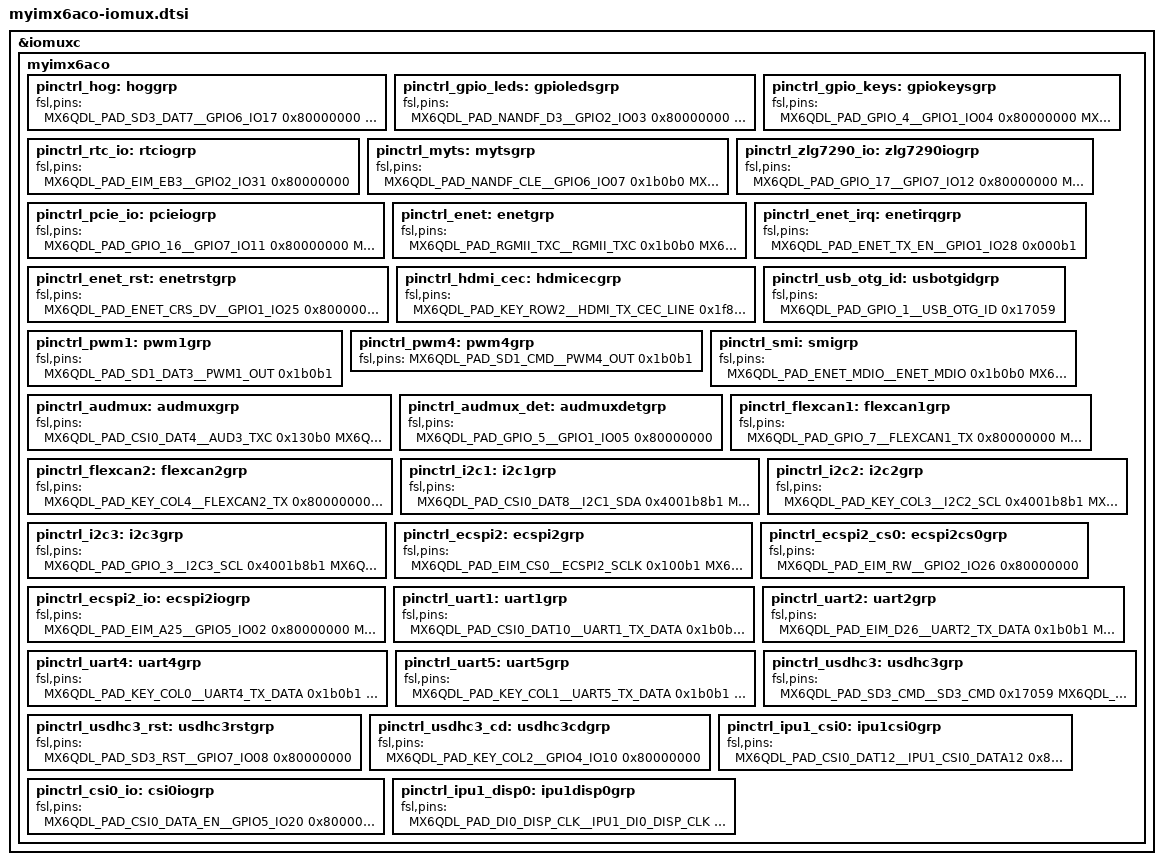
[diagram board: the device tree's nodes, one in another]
/*
 * MYZR Technology Co.,Ltd
 * http://www.myzr.com.cn
 * Tang Bin <tangb@myzr.com.cn>
 */

&iomuxc {
	myimx6aco {
		pinctrl_hog: hoggrp {
			fsl,pins = <
				MX6QDL_PAD_SD3_DAT7__GPIO6_IO17		0x80000000
				MX6QDL_PAD_SD3_DAT6__GPIO6_IO18		0x80000000
				MX6QDL_PAD_SD1_DAT0__GPIO1_IO16		0x80000000
				MX6QDL_PAD_SD1_DAT1__SD1_DATA1		0x80000000
				MX6QDL_PAD_SD1_CLK__GPIO1_IO20		0x80000000
				MX6QDL_PAD_SD1_DAT2__GPIO1_IO19		0x80000000
				MX6QDL_PAD_GPIO_19__GPIO4_IO05		0x80000000
				MX6QDL_PAD_EIM_D30__GPIO3_IO30		0x80000000
				MX6QDL_PAD_NANDF_CS3__GPIO6_IO16	0x80000000
				MX6QDL_PAD_SD2_CLK__GPIO1_IO10		0x80000000
				MX6QDL_PAD_EIM_D23__GPIO3_IO23		0x80000000
				MX6QDL_PAD_EIM_D24__GPIO3_IO24		0x80000000
				MX6QDL_PAD_EIM_D25__GPIO3_IO25		0x80000000
				MX6QDL_PAD_EIM_D31__GPIO3_IO31		0x80000000
				MX6QDL_PAD_SD2_DAT0__GPIO1_IO15		0x80000000
				MX6QDL_PAD_SD2_DAT3__GPIO1_IO12		0x80000000
				MX6QDL_PAD_SD2_DAT2__GPIO1_IO13		0x80000000
				MX6QDL_PAD_SD2_CMD__GPIO1_IO11		0x80000000
				MX6QDL_PAD_SD2_DAT1__GPIO1_IO14		0x80000000
				MX6QDL_PAD_EIM_D22__GPIO3_IO22		0x80000000
				MX6QDL_PAD_EIM_D21__GPIO3_IO21		0x80000000
				MX6QDL_PAD_EIM_DA0__GPIO3_IO00		0x80000000
				MX6QDL_PAD_EIM_DA9__GPIO3_IO09		0x80000000
				MX6QDL_PAD_EIM_DA5__GPIO3_IO05		0x80000000
				MX6QDL_PAD_EIM_BCLK__GPIO6_IO31		0x80000000
				MX6QDL_PAD_EIM_DA13__GPIO3_IO13		0x80000000
				MX6QDL_PAD_EIM_DA14__GPIO3_IO14		0x80000000
				MX6QDL_PAD_EIM_DA11__GPIO3_IO11		0x80000000
				MX6QDL_PAD_EIM_EB1__GPIO2_IO29		0x80000000
				MX6QDL_PAD_EIM_DA4__GPIO3_IO04		0x80000000
				MX6QDL_PAD_EIM_EB0__GPIO2_IO28		0x80000000
				MX6QDL_PAD_EIM_DA10__GPIO3_IO10		0x80000000
				MX6QDL_PAD_EIM_DA2__GPIO3_IO02		0x80000000
				MX6QDL_PAD_EIM_WAIT__GPIO5_IO00		0x80000000
				MX6QDL_PAD_EIM_DA15__GPIO3_IO15		0x80000000
				MX6QDL_PAD_DI0_PIN4__GPIO4_IO20		0x80000000
				MX6QDL_PAD_EIM_DA1__GPIO3_IO01		0x80000000
				MX6QDL_PAD_EIM_DA6__GPIO3_IO06		0x80000000
				MX6QDL_PAD_EIM_DA3__GPIO3_IO03		0x80000000
				MX6QDL_PAD_EIM_DA8__GPIO3_IO08		0x80000000
				MX6QDL_PAD_EIM_DA7__GPIO3_IO07		0x80000000
				MX6QDL_PAD_EIM_DA12__GPIO3_IO12		0x80000000
				MX6QDL_PAD_EIM_LBA__GPIO2_IO27		0x80000000
				
				MX6QDL_PAD_SD3_DAT5__GPIO7_IO00		0x80000000
				MX6QDL_PAD_SD3_DAT4__GPIO7_IO01		0x80000000
				
				MX6QDL_PAD_GPIO_2__GPIO1_IO02		0x80000000 /* USB_HUB_nRST */
				MX6QDL_PAD_GPIO_9__GPIO1_IO09		0x80000000 /* WDOG_B */
				
				MX6QDL_PAD_GPIO_0__CCM_CLKO1    	0x130b0
				
				/* MX6QDL_PAD_EIM_D20__GPIO3_IO20, NC */
				/* MX6QDL_PAD_NANDF_D2__GPIO2_IO02, NC */
			>;
		};
		
		pinctrl_gpio_leds: gpioledsgrp {
			fsl,pins = <
				MX6QDL_PAD_NANDF_D3__GPIO2_IO03		0x80000000 /* D10 */
				MX6QDL_PAD_ENET_RXD1__GPIO1_IO26	0x80000000 /* D11 */
				MX6QDL_PAD_ENET_TXD0__GPIO1_IO30	0x80000000 /* D12 */
				MX6QDL_PAD_ENET_RX_ER__GPIO1_IO24	0x80000000 /* D13 */
				MX6QDL_PAD_ENET_TXD1__GPIO1_IO29	0x80000000 /* D16 */
				MX6QDL_PAD_NANDF_D0__GPIO2_IO00		0x80000000 /* D17 */
				MX6QDL_PAD_NANDF_D5__GPIO2_IO05		0x80000000 /* D18 */
				MX6QDL_PAD_ENET_RXD0__GPIO1_IO27	0x80000000 /* D19 */
			>;
		};
		
		pinctrl_gpio_keys: gpiokeysgrp {
			fsl,pins = <
				MX6QDL_PAD_GPIO_4__GPIO1_IO04  		0x80000000 /* WAKE_UP */
				MX6QDL_PAD_NANDF_CS2__GPIO6_IO15	0x80000000 /* KEY_VOL+ */
				MX6QDL_PAD_NANDF_RB0__GPIO6_IO10	0x80000000 /* KEY_VOL- */
				MX6QDL_PAD_NANDF_WP_B__GPIO6_IO09	0x80000000 /* SW6 */
				MX6QDL_PAD_NANDF_D4__GPIO2_IO04		0x80000000 /* SW20 */
				MX6QDL_PAD_NANDF_D6__GPIO2_IO06		0x80000000 /* SW13 */
				MX6QDL_PAD_NANDF_D7__GPIO2_IO07		0x80000000 /* SW11 */
			>;
		};
		
		pinctrl_rtc_io: rtciogrp {
			fsl,pins = <
				MX6QDL_PAD_EIM_EB3__GPIO2_IO31 		0x80000000
			>;
		};
		
		pinctrl_myts: mytsgrp {
			fsl,pins = <
				MX6QDL_PAD_NANDF_CLE__GPIO6_IO07	0x1b0b0 /* TS_INT */
				MX6QDL_PAD_NANDF_D1__GPIO2_IO01		0x1b0b0 /* TS_RST */
			>;
		};
		
		pinctrl_zlg7290_io: zlg7290iogrp {
			fsl,pins = <
				MX6QDL_PAD_GPIO_17__GPIO7_IO12		0x80000000
				MX6QDL_PAD_GPIO_18__GPIO7_IO13		0x80000000
			>;
		};
		
		pinctrl_pcie_io: pcieiogrp {
			fsl,pins = <
				MX6QDL_PAD_GPIO_16__GPIO7_IO11		0x80000000
				MX6QDL_PAD_NANDF_CS1__GPIO6_IO14	0x80000000
				MX6QDL_PAD_NANDF_ALE__GPIO6_IO08	0x80000000
			>;
		};
		
		pinctrl_enet: enetgrp {
			fsl,pins = <
				MX6QDL_PAD_RGMII_TXC__RGMII_TXC			0x1b0b0
				MX6QDL_PAD_RGMII_TD0__RGMII_TD0			0x1b0b0
				MX6QDL_PAD_RGMII_TD1__RGMII_TD1			0x1b0b0
				MX6QDL_PAD_RGMII_TD2__RGMII_TD2			0x1b0b0
				MX6QDL_PAD_RGMII_TD3__RGMII_TD3			0x1b0b0
				MX6QDL_PAD_RGMII_TX_CTL__RGMII_TX_CTL	0x1b0b0
				MX6QDL_PAD_RGMII_RXC__RGMII_RXC			0x1b0b0
				MX6QDL_PAD_RGMII_RD0__RGMII_RD0			0x1b0b0
				MX6QDL_PAD_RGMII_RD1__RGMII_RD1			0x1b0b0
				MX6QDL_PAD_RGMII_RD2__RGMII_RD2			0x1b0b0
				MX6QDL_PAD_RGMII_RD3__RGMII_RD3			0x1b0b0
				MX6QDL_PAD_RGMII_RX_CTL__RGMII_RX_CTL	0x1b0b0
				MX6QDL_PAD_ENET_REF_CLK__ENET_TX_CLK	0x1b0b0
			>;
		};
		pinctrl_enet_irq: enetirqgrp {
			fsl,pins = <
				MX6QDL_PAD_ENET_TX_EN__GPIO1_IO28		0x000b1
			>;
		};
		pinctrl_enet_rst: enetrstgrp {
			fsl,pins = <
				MX6QDL_PAD_ENET_CRS_DV__GPIO1_IO25		0x80000000
			>;
		};
		
		pinctrl_hdmi_cec: hdmicecgrp {
			fsl,pins = <
				MX6QDL_PAD_KEY_ROW2__HDMI_TX_CEC_LINE	0x1f8b0
			>;
		};
		
		pinctrl_usb_otg_id: usbotgidgrp {
			fsl,pins = <
				MX6QDL_PAD_GPIO_1__USB_OTG_ID		0x17059
			>;
		};
		
		pinctrl_pwm1: pwm1grp {
			fsl,pins = <
				MX6QDL_PAD_SD1_DAT3__PWM1_OUT		0x1b0b1 /* DISP0_CONTRAST */
			>;
		};
		pinctrl_pwm4: pwm4grp {
			fsl,pins = <
				MX6QDL_PAD_SD1_CMD__PWM4_OUT		0x1b0b1
			>;
		};
		
		pinctrl_smi: smigrp {
			fsl,pins = <
				MX6QDL_PAD_ENET_MDIO__ENET_MDIO		0x1b0b0
				MX6QDL_PAD_ENET_MDC__ENET_MDC		0x1b0b0
			>;
		};
		
		pinctrl_audmux: audmuxgrp {
			fsl,pins = <
				MX6QDL_PAD_CSI0_DAT4__AUD3_TXC		0x130b0
				MX6QDL_PAD_CSI0_DAT5__AUD3_TXD		0x110b0
				MX6QDL_PAD_CSI0_DAT6__AUD3_TXFS		0x130b0
				MX6QDL_PAD_CSI0_DAT7__AUD3_RXD		0x130b0
			>;
		};
		pinctrl_audmux_det: audmuxdetgrp {
			fsl,pins = <
				MX6QDL_PAD_GPIO_5__GPIO1_IO05  		0x80000000
			>;
		};
		
		pinctrl_flexcan1: flexcan1grp {
			fsl,pins = <
				MX6QDL_PAD_GPIO_7__FLEXCAN1_TX		0x80000000
				MX6QDL_PAD_GPIO_8__FLEXCAN1_RX		0x80000000
			>;
		};
		pinctrl_flexcan2: flexcan2grp {
			fsl,pins = <
				MX6QDL_PAD_KEY_COL4__FLEXCAN2_TX	0x80000000
				MX6QDL_PAD_KEY_ROW4__FLEXCAN2_RX	0x80000000
			>;
		};
		
		pinctrl_i2c1: i2c1grp {
			fsl,pins = <
				MX6QDL_PAD_CSI0_DAT8__I2C1_SDA	0x4001b8b1
				MX6QDL_PAD_CSI0_DAT9__I2C1_SCL	0x4001b8b1
			>;
		};
		pinctrl_i2c2: i2c2grp {
			fsl,pins = <
				MX6QDL_PAD_KEY_COL3__I2C2_SCL	0x4001b8b1
				MX6QDL_PAD_KEY_ROW3__I2C2_SDA	0x4001b8b1
			 >;
		};
		pinctrl_i2c3: i2c3grp {
			fsl,pins = <
				MX6QDL_PAD_GPIO_3__I2C3_SCL		0x4001b8b1
				MX6QDL_PAD_GPIO_6__I2C3_SDA		0x4001b8b1
			>;
		};
		
		pinctrl_ecspi2: ecspi2grp {
			fsl,pins = <
				MX6QDL_PAD_EIM_CS0__ECSPI2_SCLK	0x100b1
				MX6QDL_PAD_EIM_OE__ECSPI2_MISO	0x100b1
				MX6QDL_PAD_EIM_CS1__ECSPI2_MOSI	0x100b1
			>;
		};
		pinctrl_ecspi2_cs0: ecspi2cs0grp {
			fsl,pins = <
				MX6QDL_PAD_EIM_RW__GPIO2_IO26	0x80000000
			>;
		};
		pinctrl_ecspi2_io: ecspi2iogrp {
			fsl,pins = <
				MX6QDL_PAD_EIM_A25__GPIO5_IO02		0x80000000
				MX6QDL_PAD_NANDF_CS0__GPIO6_IO11	0x80000000
			>;
		};
		
		pinctrl_uart1: uart1grp {
			fsl,pins = <
				MX6QDL_PAD_CSI0_DAT10__UART1_TX_DATA	0x1b0b1
				MX6QDL_PAD_CSI0_DAT11__UART1_RX_DATA	0x1b0b1
			>;
		};
		pinctrl_uart2: uart2grp {
			fsl,pins = <
				MX6QDL_PAD_EIM_D26__UART2_TX_DATA		0x1b0b1
				MX6QDL_PAD_EIM_D27__UART2_RX_DATA		0x1b0b1
				MX6QDL_PAD_EIM_D28__UART2_CTS_B			0x1b0b1
				MX6QDL_PAD_EIM_D29__UART2_RTS_B			0x1b0b1
			>;
		};
		pinctrl_uart4: uart4grp {
			fsl,pins = <
				MX6QDL_PAD_KEY_COL0__UART4_TX_DATA		0x1b0b1
				MX6QDL_PAD_KEY_ROW0__UART4_RX_DATA		0x1b0b1
			>;
		};		
		pinctrl_uart5: uart5grp {
			fsl,pins = <
				MX6QDL_PAD_KEY_COL1__UART5_TX_DATA		0x1b0b1
				MX6QDL_PAD_KEY_ROW1__UART5_RX_DATA		0x1b0b1
			>;
		};
		
		pinctrl_usdhc3: usdhc3grp {
			fsl,pins = <
				MX6QDL_PAD_SD3_CMD__SD3_CMD				0x17059
				MX6QDL_PAD_SD3_CLK__SD3_CLK				0x10059
				MX6QDL_PAD_SD3_DAT0__SD3_DATA0			0x17059
				MX6QDL_PAD_SD3_DAT1__SD3_DATA1			0x17059
				MX6QDL_PAD_SD3_DAT2__SD3_DATA2			0x17059
				MX6QDL_PAD_SD3_DAT3__SD3_DATA3			0x17059
			>;
		};
		pinctrl_usdhc3_rst: usdhc3rstgrp {
			fsl,pins = <
				MX6QDL_PAD_SD3_RST__GPIO7_IO08			0x80000000
			>;
		};
		pinctrl_usdhc3_cd: usdhc3cdgrp {
			fsl,pins = <
				MX6QDL_PAD_KEY_COL2__GPIO4_IO10 		0x80000000
			>;
		};
		
		pinctrl_ipu1_csi0: ipu1csi0grp {
			fsl,pins = <
				MX6QDL_PAD_CSI0_DAT12__IPU1_CSI0_DATA12		0x80000000
				MX6QDL_PAD_CSI0_DAT13__IPU1_CSI0_DATA13		0x80000000
				MX6QDL_PAD_CSI0_DAT14__IPU1_CSI0_DATA14		0x80000000
				MX6QDL_PAD_CSI0_DAT15__IPU1_CSI0_DATA15		0x80000000
				MX6QDL_PAD_CSI0_DAT16__IPU1_CSI0_DATA16		0x80000000
				MX6QDL_PAD_CSI0_DAT17__IPU1_CSI0_DATA17		0x80000000
				MX6QDL_PAD_CSI0_DAT18__IPU1_CSI0_DATA18		0x80000000
				MX6QDL_PAD_CSI0_DAT19__IPU1_CSI0_DATA19		0x80000000
				MX6QDL_PAD_CSI0_MCLK__IPU1_CSI0_HSYNC		0x80000000
				MX6QDL_PAD_CSI0_PIXCLK__IPU1_CSI0_PIXCLK	0x80000000
				MX6QDL_PAD_CSI0_VSYNC__IPU1_CSI0_VSYNC		0x80000000
			>;
		};
		pinctrl_csi0_io: csi0iogrp {
			fsl,pins = <
				MX6QDL_PAD_CSI0_DATA_EN__GPIO5_IO20	0x80000000 /* CSI0_PWM */
			>;
		};
		
		pinctrl_ipu1_disp0: ipu1disp0grp {
			fsl,pins = <
				MX6QDL_PAD_DI0_DISP_CLK__IPU1_DI0_DISP_CLK 0x10
				MX6QDL_PAD_DI0_PIN15__IPU1_DI0_PIN15       0x10
				MX6QDL_PAD_DI0_PIN2__IPU1_DI0_PIN02        0x10
				MX6QDL_PAD_DI0_PIN3__IPU1_DI0_PIN03        0x10
				MX6QDL_PAD_DISP0_DAT0__IPU1_DISP0_DATA00   0x10
				MX6QDL_PAD_DISP0_DAT1__IPU1_DISP0_DATA01   0x10
				MX6QDL_PAD_DISP0_DAT2__IPU1_DISP0_DATA02   0x10
				MX6QDL_PAD_DISP0_DAT3__IPU1_DISP0_DATA03   0x10
				MX6QDL_PAD_DISP0_DAT4__IPU1_DISP0_DATA04   0x10
				MX6QDL_PAD_DISP0_DAT5__IPU1_DISP0_DATA05   0x10
				MX6QDL_PAD_DISP0_DAT6__IPU1_DISP0_DATA06   0x10
				MX6QDL_PAD_DISP0_DAT7__IPU1_DISP0_DATA07   0x10
				MX6QDL_PAD_DISP0_DAT8__IPU1_DISP0_DATA08   0x10
				MX6QDL_PAD_DISP0_DAT9__IPU1_DISP0_DATA09   0x10
				MX6QDL_PAD_DISP0_DAT10__IPU1_DISP0_DATA10  0x10
				MX6QDL_PAD_DISP0_DAT11__IPU1_DISP0_DATA11  0x10
				MX6QDL_PAD_DISP0_DAT12__IPU1_DISP0_DATA12  0x10
				MX6QDL_PAD_DISP0_DAT13__IPU1_DISP0_DATA13  0x10
				MX6QDL_PAD_DISP0_DAT14__IPU1_DISP0_DATA14  0x10
				MX6QDL_PAD_DISP0_DAT15__IPU1_DISP0_DATA15  0x10
				MX6QDL_PAD_DISP0_DAT16__IPU1_DISP0_DATA16  0x10
				MX6QDL_PAD_DISP0_DAT17__IPU1_DISP0_DATA17  0x10
				MX6QDL_PAD_DISP0_DAT18__IPU1_DISP0_DATA18  0x10
				MX6QDL_PAD_DISP0_DAT19__IPU1_DISP0_DATA19  0x10
				MX6QDL_PAD_DISP0_DAT20__IPU1_DISP0_DATA20  0x10
				MX6QDL_PAD_DISP0_DAT21__IPU1_DISP0_DATA21  0x10
				MX6QDL_PAD_DISP0_DAT22__IPU1_DISP0_DATA22  0x10
				MX6QDL_PAD_DISP0_DAT23__IPU1_DISP0_DATA23  0x10
			>;
		};
	};
};
